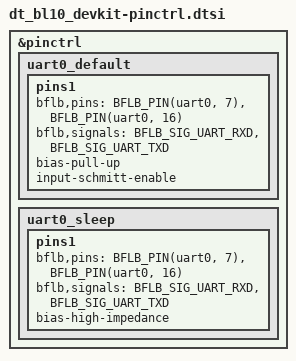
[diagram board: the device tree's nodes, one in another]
/*
 * Copyright (c) 2021, ATL Electronics
 * SPDX-License-Identifier: Apache-2.0
 */

#include <bouffalolab/bl602.dtsi>

&pinctrl {
	uart0_default: uart0_default {
		pins1 {
			bflb,pins = <BFLB_PIN(uart0,   7)>,
				    <BFLB_PIN(uart0,  16)>;
			bflb,signals = <BFLB_SIG_UART_RXD>,
				       <BFLB_SIG_UART_TXD>;
			bias-pull-up;
			input-schmitt-enable;
		};
	};
	uart0_sleep: uart0_sleep {
		pins1 {
			bflb,pins = <BFLB_PIN(uart0,   7)>,
				    <BFLB_PIN(uart0,  16)>;
			bflb,signals = <BFLB_SIG_UART_RXD>,
				       <BFLB_SIG_UART_TXD>;
			bias-high-impedance;
		};
	};
};
